# PIC18F24Q24 register map
Vendor: Microchip
Registers are 8-bit, read-write, reset 0x0 unless marked. A register's access mark holds for its fields unless they carry their own. Addresses are absolute, and some are shared; only a register's first bit layout is shown; [hi:lo] are bit positions; 'fields as' and 'values as' point back to an identical list.

## i2c
0x288 I2C1RXB ro reset not defined — I2C RECEIVE BUFFER REGISTER (power-on value xxxxxxxx)
  [7:0] RXB
0x289 I2C1TXB wo reset not defined — I2C TRANSMIT BUFFER REGISTER (power-on value xxxxxxxx)
  [7:0] TXB
0x28A I2C1CNTL reset not defined — (power-on value xxxxxxxx)
  [7:0] CNT
0x28B I2C1CNTH reset not defined — (power-on value xxxxxxxx)
  [7:0] CNT
0x28C I2C1ADB0 reset not defined — I2C ADDRESS BUFFER REGISTER 0 (power-on value xxxxxxxx)
  [7:0] ADB
0x28D I2C1ADB1 reset not defined — I2C ADDRESS BUFFER REGISTER 1 (power-on value xxxxxxxx)
  [7:0] ADB
0x28E I2C1ADR0 reset 0xFF — I2C ADDRESS REGISTER 0
  [7:0] ADR
0x28F I2C1ADR1 reset 0xFE — I2C ADDRESS REGISTER 1
  [7:1] ADR
0x290 I2C1ADR2 reset 0xFF — I2C ADDRESS REGISTER 2
  [7:0] ADR
0x291 I2C1ADR3 reset 0xFE — I2C ADDRESS REGISTER 3
  [7:1] ADR
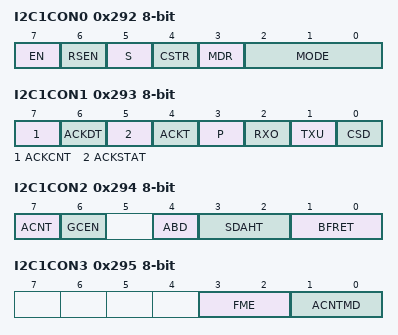
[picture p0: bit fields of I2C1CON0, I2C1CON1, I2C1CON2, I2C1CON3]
0x292 I2C1CON0 — I2C CONTROL REGISTER 0
  [7] EN
  [6] RSEN
  [5] S — (can only be set)
  [4] CSTR — (can only be cleared)
  [3] MDR ro
  [2:0] MODE
0x293 I2C1CON1 — I2C CONTROL REGISTER 1
  [7] ACKCNT
  [6] ACKDT
  [5] ACKSTAT ro
  [4] ACKT ro
  [3] P — (can only be set)
  [2] RXO
  [1] TXU
  [0] CSD
0x294 I2C1CON2 — I2C CONTROL REGISTER 2
  [7] ACNT, [6] GCEN, [4] ABD, [3:2] SDAHT, [1:0] BFRET
0x295 I2C1CON3 — I2C CONTROL REGISTER 3
  [3:2] FME, [1:0] ACNTMD
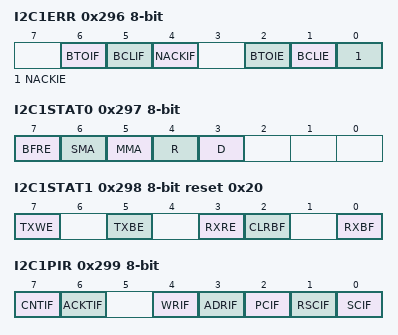
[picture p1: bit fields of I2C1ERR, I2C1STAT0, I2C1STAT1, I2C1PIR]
0x296 I2C1ERR — I2C ERROR REGISTER
  [6] BTOIF, [5] BCLIF, [4] NACKIF, [2] BTOIE, [1] BCLIE, [0] NACKIE
0x297 I2C1STAT0 ro — I2C STATUS REGISTER 0
  [7] BFRE
  [6] SMA
  [5] MMA
  [4] R — Read/Write Information bit
  [3] D — Data/Address bit
0x298 I2C1STAT1 reset 0x20 — I2C STATUS REGISTER 1
  [7] TXWE
  [5] TXBE ro
  [3] RXRE
  [2] CLRBF — (can only be set)
  [0] RXBF ro
0x299 I2C1PIR — I2C PERIPHERAL INTERRUPT FLAG REGISTER
  [7] CNTIF, [6] ACKTIF, [4] WRIF, [3] ADRIF, [2] PCIF, [1] RSCIF, [0] SCIF
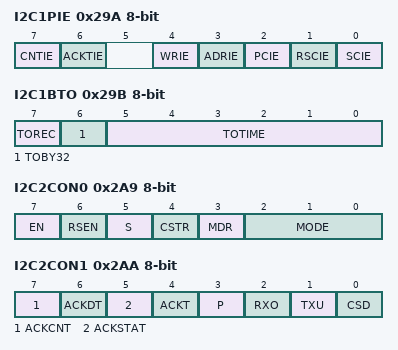
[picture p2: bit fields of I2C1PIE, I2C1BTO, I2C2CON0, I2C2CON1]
0x29A I2C1PIE — I2C PERIPHERAL INTERRUPT ENABLE REGISTER
  [7] CNTIE, [6] ACKTIE, [4] WRIE, [3] ADRIE, [2] PCIE, [1] RSCIE, [0] SCIE
0x29B I2C1BTO reset not defined — I2C BUS TIME OUT SELECTION REGISTER (power-on value xxxxxxxx)
  [7] TOREC, [6] TOBY32, [5:0] TOTIME
0x29C I2C1BAUD reset not defined — I2C BAUD RATE PRESCALER REGISTER (power-on value xxxxxxxx)
  [7:0] BAUD
0x29D I2C1CLK — I2C CLOCK SELECTION REGISTER
  [4:0] CLK
0x29E I2C1BTOC reset not defined — (power-on value ----xxxx)
  [3:0] BTOC
0x29F I2C2RXB ro reset not defined — I2C RECEIVE BUFFER REGISTER (power-on value xxxxxxxx)
  [7:0] RXB
0x2A0 I2C2TXB wo reset not defined — I2C TRANSMIT BUFFER REGISTER (power-on value xxxxxxxx)
  [7:0] TXB
0x2A1 I2C2CNTL reset not defined — (power-on value xxxxxxxx)
  [7:0] CNT
0x2A2 I2C2CNTH reset not defined — (power-on value xxxxxxxx)
  [7:0] CNT
0x2A3 I2C2ADB0 reset not defined — I2C ADDRESS BUFFER REGISTER 0 (power-on value xxxxxxxx)
  [7:0] ADB
0x2A4 I2C2ADB1 reset not defined — I2C ADDRESS BUFFER REGISTER 1 (power-on value xxxxxxxx)
  [7:0] ADB
0x2A5 I2C2ADR0 reset 0xFF — I2C ADDRESS REGISTER 0
  [7:0] ADR
0x2A6 I2C2ADR1 reset 0xFE — I2C ADDRESS REGISTER 1
  [7:1] ADR
0x2A7 I2C2ADR2 reset 0xFF — I2C ADDRESS REGISTER 2
  [7:0] ADR
0x2A8 I2C2ADR3 reset 0xFE — I2C ADDRESS REGISTER 3
  [7:1] ADR
0x2A9 I2C2CON0 — I2C CONTROL REGISTER 0
  fields as I2C1CON0
0x2AA I2C2CON1 — I2C CONTROL REGISTER 1
  fields as I2C1CON1
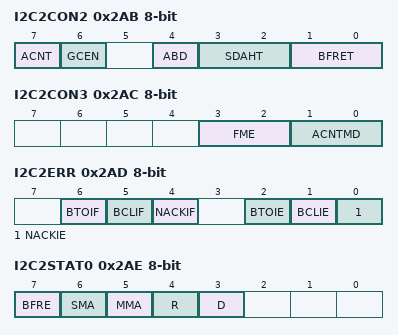
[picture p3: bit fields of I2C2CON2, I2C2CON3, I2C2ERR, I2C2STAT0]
0x2AB I2C2CON2 — I2C CONTROL REGISTER 2
  [7] ACNT, [6] GCEN, [4] ABD, [3:2] SDAHT, [1:0] BFRET
0x2AC I2C2CON3 — I2C CONTROL REGISTER 3
  [3:2] FME, [1:0] ACNTMD
0x2AD I2C2ERR — I2C ERROR REGISTER
  [6] BTOIF, [5] BCLIF, [4] NACKIF, [2] BTOIE, [1] BCLIE, [0] NACKIE
0x2AE I2C2STAT0 ro — I2C STATUS REGISTER 0
  fields as I2C1STAT0
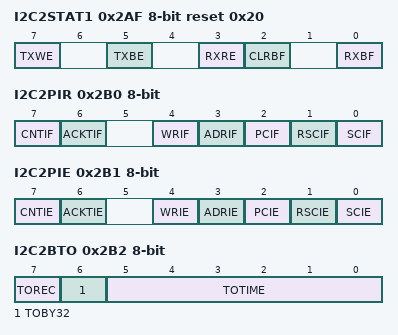
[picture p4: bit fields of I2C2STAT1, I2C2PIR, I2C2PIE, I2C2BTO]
0x2AF I2C2STAT1 reset 0x20 — I2C STATUS REGISTER 1
  fields as I2C1STAT1
0x2B0 I2C2PIR — I2C PERIPHERAL INTERRUPT FLAG REGISTER
  fields as I2C1PIR
0x2B1 I2C2PIE — I2C PERIPHERAL INTERRUPT ENABLE REGISTER
  fields as I2C1PIE
0x2B2 I2C2BTO reset not defined — I2C BUS TIME OUT SELECTION REGISTER (power-on value xxxxxxxx)
  [7] TOREC, [6] TOBY32, [5:0] TOTIME
0x2B3 I2C2BAUD reset not defined — I2C BAUD RATE PRESCALER REGISTER (power-on value xxxxxxxx)
  [7:0] BAUD
0x2B4 I2C2CLK — I2C CLOCK SELECTION REGISTER
  [4:0] CLK
0x2B5 I2C2BTOC reset not defined — (power-on value ----xxxx)
  [3:0] BTOC
